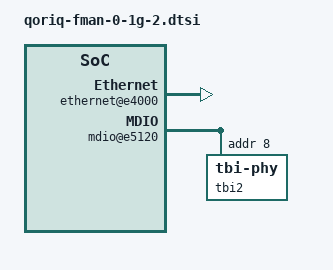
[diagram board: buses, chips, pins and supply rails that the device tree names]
// SPDX-License-Identifier: (GPL-2.0+ OR BSD-3-Clause)
/*
 * QorIQ FMan 1g port #2 device tree stub [ controller @ offset 0x400000 ]
 *
 * Copyright 2011 - 2015 Freescale Semiconductor Inc.
 * Copyright 2020 NXP
 *
 */

fman@400000 {
	fman0_rx_0x0a: port@8a000 {
		cell-index = <0xa>;
		compatible = "fsl,fman-v2-port-rx";
		reg = <0x8a000 0x1000>;
	};

	fman0_tx_0x2a: port@aa000 {
		cell-index = <0x2a>;
		compatible = "fsl,fman-v2-port-tx";
		reg = <0xaa000 0x1000>;
	};

	ethernet@e4000 {
		cell-index = <2>;
		compatible = "fsl,fman-dtsec";
		reg = <0xe4000 0x1000>;
		fsl,fman-ports = <&fman0_rx_0x0a &fman0_tx_0x2a>;
		tbi-handle = <&tbi2>;
		ptp-timer = <&ptp_timer0>;
	};

	mdio@e5120 {
		#address-cells = <1>;
		#size-cells = <0>;
		compatible = "fsl,fman-mdio";
		reg = <0xe5120 0xee0>;

		tbi2: tbi-phy@8 {
			reg = <0x8>;
			device_type = "tbi-phy";
		};
	};
};
